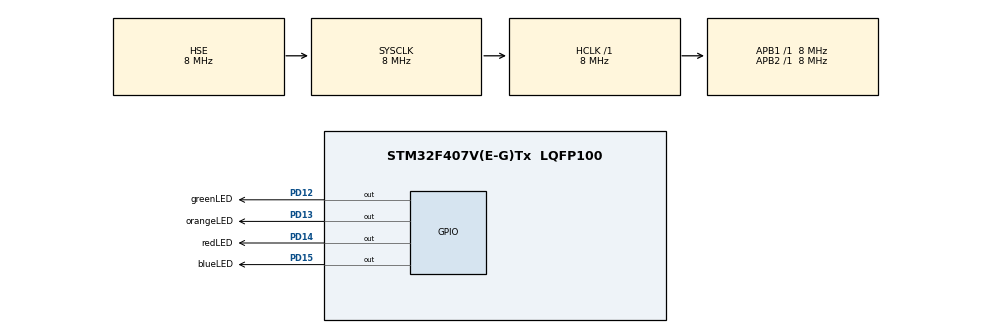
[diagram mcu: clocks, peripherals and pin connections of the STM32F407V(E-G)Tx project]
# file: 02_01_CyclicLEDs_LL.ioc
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Mcu.Family=STM32F4
Mcu.Name=STM32F407V(E-G)Tx
Mcu.Package=LQFP100
NVIC.PriorityGroup=NVIC_PRIORITYGROUP_4
PD12.GPIO_Label=greenLED
PD12.Signal=GPIO_Output
PD13.GPIO_Label=orangeLED
PD13.Signal=GPIO_Output
PD14.GPIO_Label=redLED
PD14.Signal=GPIO_Output
PD15.GPIO_Label=blueLED
PD15.Signal=GPIO_Output
PH0-OSC_IN.Mode=HSE-External-Oscillator
PH0-OSC_IN.Signal=RCC_OSC_IN
PH1-OSC_OUT.Mode=HSE-External-Oscillator
PH1-OSC_OUT.Signal=RCC_OSC_OUT
ProjectManager.HeapSize=0x200
ProjectManager.StackSize=0x400
ProjectManager.TargetToolchain=STM32CubeIDE
RCC.AHBFreq_Value=8000000
RCC.APB1Freq_Value=8000000
RCC.APB1TimFreq_Value=8000000
RCC.APB2Freq_Value=8000000
RCC.APB2TimFreq_Value=8000000
RCC.CortexFreq_Value=8000000
RCC.HCLKFreq_Value=8000000
RCC.HSE_VALUE=8000000
RCC.HSI_VALUE=16000000
RCC.LSE_VALUE=32768
RCC.SYSCLKFreq_VALUE=8000000
RCC.SYSCLKSource=RCC_SYSCLKSOURCE_HSE
RCC.VCOOutputFreq_Value=192000000
board=custom

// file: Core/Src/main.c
/* USER CODE BEGIN Header */
/**
  ******************************************************************************
  * @file           : main.c
  * @brief          : Main program body
  ******************************************************************************
  * @attention
  *
  * Copyright (c) 2024 STMicroelectronics.
  * All rights reserved.
  *
  * This software is licensed under terms that can be found in the LICENSE file
  * in the root directory of this software component.
  * If no LICENSE file comes with this software, it is provided AS-IS.
  *
  ******************************************************************************
  */
/* USER CODE END Header */
#include "main.h"

void SystemClock_Config(void);
static void MX_GPIO_Init(void);
/* USER CODE BEGIN PFP */
void myDelay(uint16_t delay);
/* USER CODE END PFP */

int main(void)
{

  /* USER CODE BEGIN 1 */
	uint32_t value = greenLED_Pin;
  /* USER CODE END 1 */

  /* MCU Configuration--------------------------------------------------------*/

  /* Reset of all peripherals, Initializes the Flash interface and the Systick. */
  HAL_Init();

  /* Configure the system clock */
  SystemClock_Config();

  /* Initialize all configured peripherals */
  MX_GPIO_Init();
  /* USER CODE BEGIN 2 */

  uint32_t freq = HAL_RCC_GetSysClockFreq();
  /* USER CODE END 2 */

  /* Infinite loop */
  /* USER CODE BEGIN WHILE */
  while (1)
  {
	  LL_GPIO_WriteOutputPort(greenLED_GPIO_Port, value);
	  //LL_mDelay(200
	  myDelay(1000);
	  value = value << 1;
	  if(value > blueLED_Pin){
		  value = greenLED_Pin;
	  }
	  // the LEDs pins are consecutive so we can just move the bit one position to the left (one position up)
	  // and reset it when the number value gets bigger than the last diode, resets to the first diode

    /* USER CODE END WHILE */

  }
}

void SystemClock_Config(void)
{
  RCC_OscInitTypeDef RCC_OscInitStruct = {0};
  RCC_ClkInitTypeDef RCC_ClkInitStruct = {0};

  /** Configure the main internal regulator output voltage
  */
  __HAL_RCC_PWR_CLK_ENABLE();
  __HAL_PWR_VOLTAGESCALING_CONFIG(PWR_REGULATOR_VOLTAGE_SCALE1);

  /** Initializes the RCC Oscillators according to the specified parameters
  * in the RCC_OscInitTypeDef structure.
  */
  RCC_OscInitStruct.OscillatorType = RCC_OSCILLATORTYPE_HSE;
  RCC_OscInitStruct.HSEState = RCC_HSE_ON;
  RCC_OscInitStruct.PLL.PLLState = RCC_PLL_NONE;
  if (HAL_RCC_OscConfig(&RCC_OscInitStruct) != HAL_OK)
  {
    Error_Handler();
  }

  /** Initializes the CPU, AHB and APB buses clocks
  */
  RCC_ClkInitStruct.ClockType = RCC_CLOCKTYPE_HCLK|RCC_CLOCKTYPE_SYSCLK
                              |RCC_CLOCKTYPE_PCLK1|RCC_CLOCKTYPE_PCLK2;
  RCC_ClkInitStruct.SYSCLKSource = RCC_SYSCLKSOURCE_HSE;
  RCC_ClkInitStruct.AHBCLKDivider = RCC_SYSCLK_DIV1;
  RCC_ClkInitStruct.APB1CLKDivider = RCC_HCLK_DIV1;
  RCC_ClkInitStruct.APB2CLKDivider = RCC_HCLK_DIV1;

  if (HAL_RCC_ClockConfig(&RCC_ClkInitStruct, FLASH_LATENCY_0) != HAL_OK)
  {
    Error_Handler();
  }
}

static void MX_GPIO_Init(void)
{
  LL_GPIO_InitTypeDef GPIO_InitStruct = {0};

  /* GPIO Ports Clock Enable */
  LL_AHB1_GRP1_EnableClock(LL_AHB1_GRP1_PERIPH_GPIOH);
  LL_AHB1_GRP1_EnableClock(LL_AHB1_GRP1_PERIPH_GPIOD);

  /**/
  LL_GPIO_ResetOutputPin(GPIOD, greenLED_Pin|orangeLED_Pin|redLED_Pin|blueLED_Pin);

  /**/
  GPIO_InitStruct.Pin = greenLED_Pin|orangeLED_Pin|redLED_Pin|blueLED_Pin;
  GPIO_InitStruct.Mode = LL_GPIO_MODE_OUTPUT;
  GPIO_InitStruct.Speed = LL_GPIO_SPEED_FREQ_LOW;
  GPIO_InitStruct.OutputType = LL_GPIO_OUTPUT_PUSHPULL;
  GPIO_InitStruct.Pull = LL_GPIO_PULL_NO;
  LL_GPIO_Init(GPIOD, &GPIO_InitStruct);

}

/* USER CODE BEGIN 4 */
void myDelay(uint16_t delay){
	// get system clock 8 MGHz
	uint32_t time = delay * 1000UL; // sysCLK is 2 times slower than the internal one so we use 2 times lower coefficient
	while(time--);
}
/* USER CODE END 4 */

void Error_Handler(void)
{
  __disable_irq();
  while (1)
  {
  }
}
